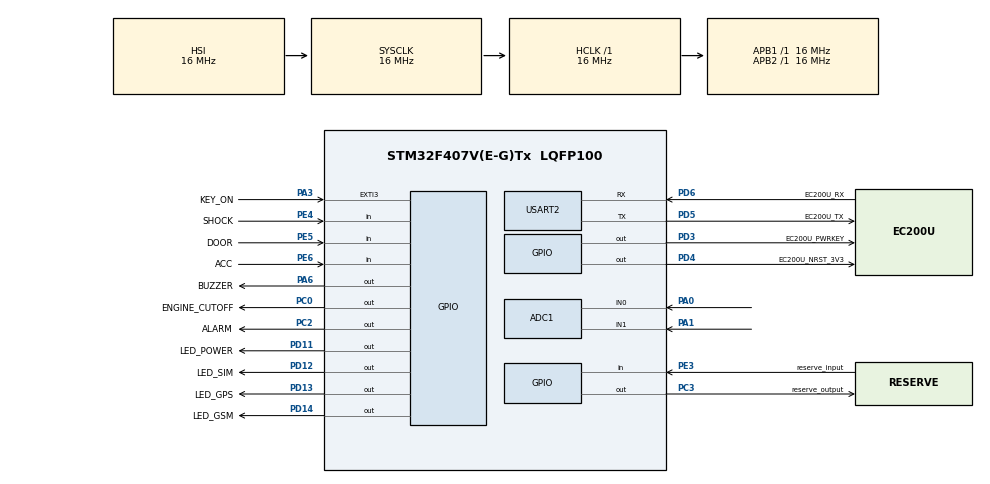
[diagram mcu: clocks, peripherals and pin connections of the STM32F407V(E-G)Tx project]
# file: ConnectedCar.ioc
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ADC1.Channel-0\#ChannelRegularConversion=ADC_CHANNEL_0
ADC1.NbrOfConversionFlag=1
ADC1.Rank-0\#ChannelRegularConversion=1
ADC1.SamplingTime-0\#ChannelRegularConversion=ADC_SAMPLETIME_3CYCLES
ADC1.master=1
Mcu.Family=STM32F4
Mcu.Name=STM32F407V(E-G)Tx
Mcu.Package=LQFP100
NVIC.EXTI3_IRQn=true\:0\:0\:false\:false\:true\:true\:true\:true
NVIC.PriorityGroup=NVIC_PRIORITYGROUP_4
PA0-WKUP.Signal=ADCx_IN0
PA1.Signal=ADCx_IN1
PA13.Mode=Serial_Wire
PA13.Signal=SYS_JTMS-SWDIO
PA14.Mode=Serial_Wire
PA14.Signal=SYS_JTCK-SWCLK
PA3.GPIO_Label=KEY_ON
PA3.GPIO_PuPd=GPIO_PULLDOWN
PA3.Signal=GPXTI3
PA6.GPIO_Label=BUZZER
PA6.Signal=GPIO_Output
PC0.GPIO_Label=ENGINE_CUTOFF
PC0.Signal=GPIO_Output
PC14-OSC32_IN.Mode=LSE-External-Oscillator
PC14-OSC32_IN.Signal=RCC_OSC32_IN
PC15-OSC32_OUT.Mode=LSE-External-Oscillator
PC15-OSC32_OUT.Signal=RCC_OSC32_OUT
PC2.GPIO_Label=ALARM
PC2.Signal=GPIO_Output
PC3.GPIO_Label=reserve_output
PC3.Signal=GPIO_Output
PD11.GPIO_Label=LED_POWER
PD11.GPIO_PuPd=GPIO_PULLDOWN
PD11.Signal=GPIO_Output
PD12.GPIO_Label=LED_SIM
PD12.GPIO_PuPd=GPIO_PULLDOWN
PD12.Signal=GPIO_Output
PD13.GPIO_Label=LED_GPS
PD13.GPIO_PuPd=GPIO_PULLDOWN
PD13.Signal=GPIO_Output
PD14.GPIO_Label=LED_GSM
PD14.GPIO_PuPd=GPIO_PULLDOWN
PD14.Signal=GPIO_Output
PD3.GPIO_Label=EC200U_PWRKEY
PD3.GPIO_PuPd=GPIO_PULLDOWN
PD3.Signal=GPIO_Output
PD4.GPIO_Label=EC200U_NRST_3V3
PD4.GPIO_PuPd=GPIO_PULLDOWN
PD4.Signal=GPIO_Output
PD5.GPIO_Label=EC200U_TX
PD5.Mode=Asynchronous
PD5.Signal=USART2_TX
PD6.GPIO_Label=EC200U_RX
PD6.Mode=Asynchronous
PD6.Signal=USART2_RX
PE3.GPIO_Label=reserve_input
PE3.Signal=GPIO_Input
PE4.GPIO_Label=SHOCK
PE4.Signal=GPIO_Input
PE5.GPIO_Label=DOOR
PE5.Signal=GPIO_Input
PE6.GPIO_Label=ACC
PE6.Signal=GPIO_Input
ProjectManager.HeapSize=0x200
ProjectManager.StackSize=0x400
ProjectManager.TargetToolchain=STM32CubeIDE
RCC.48MHZClocksFreq_Value=48000000
RCC.AHBFreq_Value=16000000
RCC.APB1Freq_Value=16000000
RCC.APB1TimFreq_Value=16000000
RCC.APB2Freq_Value=16000000
RCC.APB2TimFreq_Value=16000000
RCC.CortexFreq_Value=16000000
RCC.HCLKFreq_Value=16000000
RCC.HSE_VALUE=12000000
RCC.HSI_VALUE=16000000
RCC.PLLM=8
RCC.PLLN=72
RCC.PLLQ=3
RCC.SYSCLKFreq_VALUE=16000000
RCC.VCOOutputFreq_Value=144000000
SH.ADCx_IN0.0=ADC1_IN0,IN0
SH.ADCx_IN1.0=ADC1_IN1,IN1
USART2.VirtualMode=VM_ASYNC
board=custom

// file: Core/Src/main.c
/* USER CODE BEGIN Header */
/**
  ******************************************************************************
  * @file           : main.c
  * @brief          : Main program body
  ******************************************************************************
  * @attention
  *
  * Copyright (c) 2026 STMicroelectronics.
  * All rights reserved.
  *
  * This software is licensed under terms that can be found in the LICENSE file
  * in the root directory of this software component.
  * If no LICENSE file comes with this software, it is provided AS-IS.
  *
  ******************************************************************************
  */
/* USER CODE END Header */
#include "main.h"
/* Git practice: LED test */

/* USER CODE BEGIN Includes */
#include "firmware_main.h" /* از repo/firmware (نه این پروژه CubeIDE) - نگاه کن
                             * docs/03-infrastructure-contracts/target-integration.md
                             * برای افزودن firmware/include و firmware/src به
                             * مسیرهای این پروژه (Project Properties). */
/* USER CODE END Includes */

ADC_HandleTypeDef hadc1;

UART_HandleTypeDef huart2;

void SystemClock_Config(void);
static void MX_GPIO_Init(void);
static void MX_USART2_UART_Init(void);
static void MX_ADC1_Init(void);

int main(void)
{

  /* MCU Configuration--------------------------------------------------------*/

  /* Reset of all peripherals, Initializes the Flash interface and the Systick. */
  HAL_Init();

  /* Configure the system clock */
  SystemClock_Config();

  /* Initialize all configured peripherals */
  MX_GPIO_Init();
  MX_USART2_UART_Init();
  MX_ADC1_Init();
  /* USER CODE BEGIN 2 */

  /* Firmware_Main() هرگز برنمی‌گردد - خودش Super Loop کامل Firmware
   * (repo/firmware) است. while(1) زیر عمداً توسط CubeMX تولید شده و
   * هیچ‌وقت اجرا نمی‌شود؛ آن را دست‌نخورده می‌گذاریم تا CubeMX بتواند
   * روی این فایل Regenerate کند بدون تداخل با این USER CODE. */
  Firmware_Main();

  /* USER CODE END 2 */

  /* Infinite loop */
  while (1)
  {

  }
}

void SystemClock_Config(void)
{
  RCC_OscInitTypeDef RCC_OscInitStruct = {0};
  RCC_ClkInitTypeDef RCC_ClkInitStruct = {0};

  /** Configure the main internal regulator output voltage
  */
  __HAL_RCC_PWR_CLK_ENABLE();
  __HAL_PWR_VOLTAGESCALING_CONFIG(PWR_REGULATOR_VOLTAGE_SCALE1);

  /** Initializes the RCC Oscillators according to the specified parameters
  * in the RCC_OscInitTypeDef structure.
  */
  RCC_OscInitStruct.OscillatorType = RCC_OSCILLATORTYPE_HSI;
  RCC_OscInitStruct.HSIState = RCC_HSI_ON;
  RCC_OscInitStruct.HSICalibrationValue = RCC_HSICALIBRATION_DEFAULT;
  RCC_OscInitStruct.PLL.PLLState = RCC_PLL_NONE;
  if (HAL_RCC_OscConfig(&RCC_OscInitStruct) != HAL_OK)
  {
    Error_Handler();
  }

  /** Initializes the CPU, AHB and APB buses clocks
  */
  RCC_ClkInitStruct.ClockType = RCC_CLOCKTYPE_HCLK|RCC_CLOCKTYPE_SYSCLK
                              |RCC_CLOCKTYPE_PCLK1|RCC_CLOCKTYPE_PCLK2;
  RCC_ClkInitStruct.SYSCLKSource = RCC_SYSCLKSOURCE_HSI;
  RCC_ClkInitStruct.AHBCLKDivider = RCC_SYSCLK_DIV1;
  RCC_ClkInitStruct.APB1CLKDivider = RCC_HCLK_DIV1;
  RCC_ClkInitStruct.APB2CLKDivider = RCC_HCLK_DIV1;

  if (HAL_RCC_ClockConfig(&RCC_ClkInitStruct, FLASH_LATENCY_0) != HAL_OK)
  {
    Error_Handler();
  }
}

static void MX_ADC1_Init(void)
{

  ADC_ChannelConfTypeDef sConfig = {0};

  /** Configure the global features of the ADC (Clock, Resolution, Data Alignment and number of conversion)
  */
  hadc1.Instance = ADC1;
  hadc1.Init.ClockPrescaler = ADC_CLOCK_SYNC_PCLK_DIV2;
  hadc1.Init.Resolution = ADC_RESOLUTION_12B;
  hadc1.Init.ScanConvMode = DISABLE;
  hadc1.Init.ContinuousConvMode = DISABLE;
  hadc1.Init.DiscontinuousConvMode = DISABLE;
  hadc1.Init.ExternalTrigConvEdge = ADC_EXTERNALTRIGCONVEDGE_NONE;
  hadc1.Init.ExternalTrigConv = ADC_SOFTWARE_START;
  hadc1.Init.DataAlign = ADC_DATAALIGN_RIGHT;
  hadc1.Init.NbrOfConversion = 1;
  hadc1.Init.DMAContinuousRequests = DISABLE;
  hadc1.Init.EOCSelection = ADC_EOC_SINGLE_CONV;
  if (HAL_ADC_Init(&hadc1) != HAL_OK)
  {
    Error_Handler();
  }

  /** Configure for the selected ADC regular channel its corresponding rank in the sequencer and its sample time.
  */
  sConfig.Channel = ADC_CHANNEL_0;
  sConfig.Rank = 1;
  sConfig.SamplingTime = ADC_SAMPLETIME_3CYCLES;
  if (HAL_ADC_ConfigChannel(&hadc1, &sConfig) != HAL_OK)
  {
    Error_Handler();
  }

}

static void MX_USART2_UART_Init(void)
{

  huart2.Instance = USART2;
  huart2.Init.BaudRate = 115200;
  huart2.Init.WordLength = UART_WORDLENGTH_8B;
  huart2.Init.StopBits = UART_STOPBITS_1;
  huart2.Init.Parity = UART_PARITY_NONE;
  huart2.Init.Mode = UART_MODE_TX_RX;
  huart2.Init.HwFlowCtl = UART_HWCONTROL_NONE;
  huart2.Init.OverSampling = UART_OVERSAMPLING_16;
  if (HAL_UART_Init(&huart2) != HAL_OK)
  {
    Error_Handler();
  }

}

static void MX_GPIO_Init(void)
{
  GPIO_InitTypeDef GPIO_InitStruct = {0};

  /* GPIO Ports Clock Enable */
  __HAL_RCC_GPIOE_CLK_ENABLE();
  __HAL_RCC_GPIOC_CLK_ENABLE();
  __HAL_RCC_GPIOA_CLK_ENABLE();
  __HAL_RCC_GPIOD_CLK_ENABLE();

  /*Configure GPIO pin Output Level */
  HAL_GPIO_WritePin(GPIOC, ENGINE_CUTOFF_Pin|ALARM_Pin|reserve_output_Pin, GPIO_PIN_RESET);

  /*Configure GPIO pin Output Level */
  HAL_GPIO_WritePin(BUZZER_GPIO_Port, BUZZER_Pin, GPIO_PIN_RESET);

  /*Configure GPIO pin Output Level */
  HAL_GPIO_WritePin(GPIOD, LED_POWER_Pin|LED_SIM_Pin|LED_GPS_Pin|LED_GSM_Pin
                          |EC200U_PWRKEY_Pin|EC200U_NRST_3V3_Pin, GPIO_PIN_RESET);

  /*Configure GPIO pins : reserve_input_Pin SHOCK_Pin DOOR_Pin ACC_Pin */
  GPIO_InitStruct.Pin = reserve_input_Pin|SHOCK_Pin|DOOR_Pin|ACC_Pin;
  GPIO_InitStruct.Mode = GPIO_MODE_INPUT;
  GPIO_InitStruct.Pull = GPIO_NOPULL;
  HAL_GPIO_Init(GPIOE, &GPIO_InitStruct);

  /*Configure GPIO pins : ENGINE_CUTOFF_Pin ALARM_Pin reserve_output_Pin */
  GPIO_InitStruct.Pin = ENGINE_CUTOFF_Pin|ALARM_Pin|reserve_output_Pin;
  GPIO_InitStruct.Mode = GPIO_MODE_OUTPUT_PP;
  GPIO_InitStruct.Pull = GPIO_NOPULL;
  GPIO_InitStruct.Speed = GPIO_SPEED_FREQ_LOW;
  HAL_GPIO_Init(GPIOC, &GPIO_InitStruct);

  /*Configure GPIO pin : KEY_ON_Pin */
  GPIO_InitStruct.Pin = KEY_ON_Pin;
  GPIO_InitStruct.Mode = GPIO_MODE_IT_RISING;
  GPIO_InitStruct.Pull = GPIO_PULLDOWN;
  HAL_GPIO_Init(KEY_ON_GPIO_Port, &GPIO_InitStruct);

  /*Configure GPIO pin : BUZZER_Pin */
  GPIO_InitStruct.Pin = BUZZER_Pin;
  GPIO_InitStruct.Mode = GPIO_MODE_OUTPUT_PP;
  GPIO_InitStruct.Pull = GPIO_NOPULL;
  GPIO_InitStruct.Speed = GPIO_SPEED_FREQ_LOW;
  HAL_GPIO_Init(BUZZER_GPIO_Port, &GPIO_InitStruct);

  /*Configure GPIO pins : LED_POWER_Pin LED_SIM_Pin LED_GPS_Pin LED_GSM_Pin
                           EC200U_PWRKEY_Pin EC200U_NRST_3V3_Pin */
  GPIO_InitStruct.Pin = LED_POWER_Pin|LED_SIM_Pin|LED_GPS_Pin|LED_GSM_Pin
                          |EC200U_PWRKEY_Pin|EC200U_NRST_3V3_Pin;
  GPIO_InitStruct.Mode = GPIO_MODE_OUTPUT_PP;
  GPIO_InitStruct.Pull = GPIO_PULLDOWN;
  GPIO_InitStruct.Speed = GPIO_SPEED_FREQ_LOW;
  HAL_GPIO_Init(GPIOD, &GPIO_InitStruct);

  /* EXTI interrupt init*/
  HAL_NVIC_SetPriority(EXTI3_IRQn, 0, 0);
  HAL_NVIC_EnableIRQ(EXTI3_IRQn);

}

void Error_Handler(void)
{
  __disable_irq();
  while (1)
  {
  }
}
